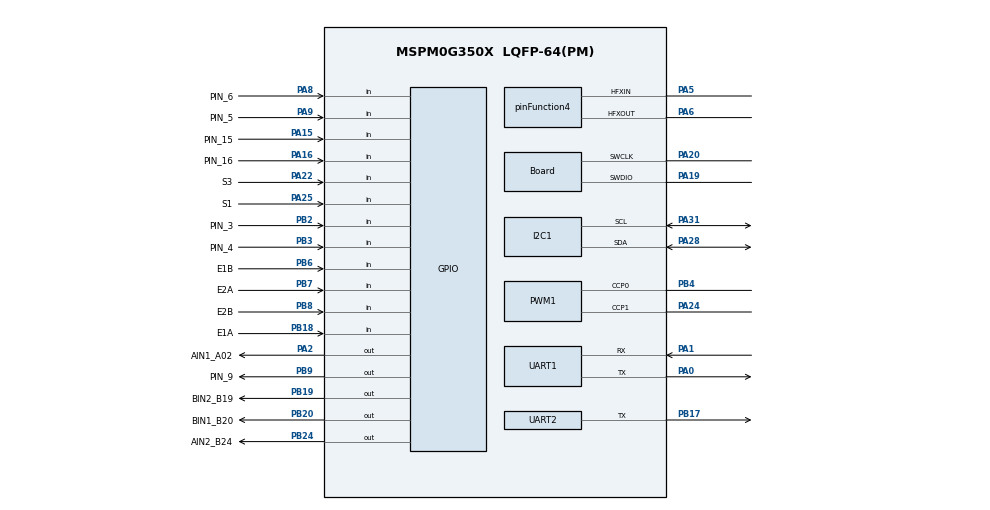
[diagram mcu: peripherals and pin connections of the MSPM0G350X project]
/**
 * @cliArgs --device "MSPM0G350X" --package "LQFP-64(PM)" --part "Default" --product "mspm0_sdk@2.01.00.03"
 * @versions {"tool":"1.20.0+3587"}
 */

/**
 * Import the modules used in this configuration.
 */
const GPIO          = scripting.addModule("/ti/driverlib/GPIO", {}, false);
const GPIO1         = GPIO.addInstance();
const GPIO2         = GPIO.addInstance();
const GPIO3         = GPIO.addInstance();
const GPIO4         = GPIO.addInstance();
const GPIO5         = GPIO.addInstance();
const GPIO6         = GPIO.addInstance();
const GPIO7         = GPIO.addInstance();
const GPIO8         = GPIO.addInstance();
const GPIO9         = GPIO.addInstance();
const GPIO10        = GPIO.addInstance();
const GPIO11        = GPIO.addInstance();
const GPIO12        = GPIO.addInstance();
const GPIO13        = GPIO.addInstance();
const GPIO14        = GPIO.addInstance();
const GPIO15        = GPIO.addInstance();
const GPIO16        = GPIO.addInstance();
const GPIO17        = GPIO.addInstance();
const I2C           = scripting.addModule("/ti/driverlib/I2C", {}, false);
const I2C1          = I2C.addInstance();
const PWM           = scripting.addModule("/ti/driverlib/PWM", {}, false);
const PWM1          = PWM.addInstance();
const PWM2          = PWM.addInstance();
const SYSCTL        = scripting.addModule("/ti/driverlib/SYSCTL");
const SYSTICK       = scripting.addModule("/ti/driverlib/SYSTICK");
const TIMER         = scripting.addModule("/ti/driverlib/TIMER", {}, false);
const TIMER1        = TIMER.addInstance();
const TIMER2        = TIMER.addInstance();
const UART          = scripting.addModule("/ti/driverlib/UART", {}, false);
const UART1         = UART.addInstance();
const UART2         = UART.addInstance();
const UART3         = UART.addInstance();
const UART4         = UART.addInstance();
const ProjectConfig = scripting.addModule("/ti/project_config/ProjectConfig");

/**
 * Write custom configuration values to the imported modules.
 */
const divider9       = system.clockTree["UDIV"];
divider9.divideValue = 2;

const gate7  = system.clockTree["MFCLKGATE"];
gate7.enable = true;

const multiplier2         = system.clockTree["PLL_QDIV"];
multiplier2.multiplyValue = 4;

const mux3       = system.clockTree["EXCLKMUX"];
mux3.inputSelect = "EXCLKMUX_PLLCLK1_OUT";

const mux4       = system.clockTree["EXHFMUX"];
mux4.inputSelect = "EXHFMUX_XTAL";

const mux8       = system.clockTree["HSCLKMUX"];
mux8.inputSelect = "HSCLKMUX_SYSPLL0";

const mux12       = system.clockTree["SYSPLLMUX"];
mux12.inputSelect = "zSYSPLLMUX_HFCLK";

const pinFunction4                        = system.clockTree["HFXT"];
pinFunction4.inputFreq                    = 40;
pinFunction4.enable                       = true;
pinFunction4.HFXTStartup                  = 10;
pinFunction4.peripheral.$assign           = "SYSCTL";
pinFunction4.peripheral.hfxInPin.$assign  = "PA5";
pinFunction4.peripheral.hfxOutPin.$assign = "PA6";

GPIO1.$name                              = "LED1";
GPIO1.port                               = "PORTA";
GPIO1.associatedPins[0].$name            = "PIN_14";
GPIO1.associatedPins[0].assignedPin      = "14";
GPIO1.associatedPins[0].internalResistor = "PULL_UP";

const Board                       = scripting.addModule("/ti/driverlib/Board", {}, false);
Board.peripheral.$assign          = "DEBUGSS";
Board.peripheral.swclkPin.$assign = "PA20";
Board.peripheral.swdioPin.$assign = "PA19";

GPIO2.$name                              = "KEY";
GPIO2.port                               = "PORTA";
GPIO2.associatedPins.create(4);
GPIO2.associatedPins[0].direction        = "INPUT";
GPIO2.associatedPins[0].interruptEn      = true;
GPIO2.associatedPins[0].$name            = "PIN_15";
GPIO2.associatedPins[0].assignedPin      = "15";
GPIO2.associatedPins[0].polarity         = "RISE";
GPIO2.associatedPins[0].internalResistor = "PULL_UP";
GPIO2.associatedPins[0].pin.$assign      = "PA15";
GPIO2.associatedPins[1].$name            = "PIN_16";
GPIO2.associatedPins[1].assignedPin      = "16";
GPIO2.associatedPins[1].direction        = "INPUT";
GPIO2.associatedPins[1].internalResistor = "PULL_UP";
GPIO2.associatedPins[1].pin.$assign      = "PA16";
GPIO2.associatedPins[2].direction        = "INPUT";
GPIO2.associatedPins[2].internalResistor = "PULL_UP";
GPIO2.associatedPins[2].$name            = "PIN_23";
GPIO2.associatedPins[3].assignedPin      = "21";
GPIO2.associatedPins[3].$name            = "PIN_21";
GPIO2.associatedPins[3].direction        = "INPUT";
GPIO2.associatedPins[3].internalResistor = "PULL_UP";

GPIO3.$name                               = "ENCODER";
GPIO3.associatedPins.create(4);
GPIO3.associatedPins[0].$name             = "E1A";
GPIO3.associatedPins[0].direction         = "INPUT";
GPIO3.associatedPins[0].assignedPort      = "PORTB";
GPIO3.associatedPins[0].assignedPin       = "18";
GPIO3.associatedPins[0].interruptEn       = true;
GPIO3.associatedPins[0].interruptPriority = "0";
GPIO3.associatedPins[0].polarity          = "RISE";
GPIO3.associatedPins[0].pin.$assign       = "PB18";
GPIO3.associatedPins[1].$name             = "E1B";
GPIO3.associatedPins[1].direction         = "INPUT";
GPIO3.associatedPins[1].assignedPort      = "PORTB";
GPIO3.associatedPins[1].assignedPin       = "6";
GPIO3.associatedPins[1].interruptEn       = true;
GPIO3.associatedPins[1].interruptPriority = "0";
GPIO3.associatedPins[1].polarity          = "RISE";
GPIO3.associatedPins[1].pin.$assign       = "PB6";
GPIO3.associatedPins[2].$name             = "E2A";
GPIO3.associatedPins[2].direction         = "INPUT";
GPIO3.associatedPins[2].assignedPort      = "PORTB";
GPIO3.associatedPins[2].assignedPin       = "7";
GPIO3.associatedPins[2].interruptEn       = true;
GPIO3.associatedPins[2].interruptPriority = "0";
GPIO3.associatedPins[2].polarity          = "RISE";
GPIO3.associatedPins[2].pin.$assign       = "PB7";
GPIO3.associatedPins[3].$name             = "E2B";
GPIO3.associatedPins[3].direction         = "INPUT";
GPIO3.associatedPins[3].assignedPort      = "PORTB";
GPIO3.associatedPins[3].assignedPin       = "8";
GPIO3.associatedPins[3].interruptEn       = true;
GPIO3.associatedPins[3].interruptPriority = "0";
GPIO3.associatedPins[3].polarity          = "RISE";
GPIO3.associatedPins[3].pin.$assign       = "PB8";

GPIO4.$name                          = "MOTOR";
GPIO4.associatedPins.create(4);
GPIO4.associatedPins[0].$name        = "AIN1_A02";
GPIO4.associatedPins[0].assignedPort = "PORTA";
GPIO4.associatedPins[0].assignedPin  = "2";
GPIO4.associatedPins[0].pin.$assign  = "PA2";
GPIO4.associatedPins[1].$name        = "AIN2_B24";
GPIO4.associatedPins[1].assignedPort = "PORTB";
GPIO4.associatedPins[1].assignedPin  = "24";
GPIO4.associatedPins[1].pin.$assign  = "PB24";
GPIO4.associatedPins[2].$name        = "BIN1_B20";
GPIO4.associatedPins[2].assignedPort = "PORTB";
GPIO4.associatedPins[2].assignedPin  = "20";
GPIO4.associatedPins[2].pin.$assign  = "PB20";
GPIO4.associatedPins[3].$name        = "BIN2_B19";
GPIO4.associatedPins[3].assignedPort = "PORTB";
GPIO4.associatedPins[3].assignedPin  = "19";
GPIO4.associatedPins[3].pin.$assign  = "PB19";

GPIO5.$name                          = "TRACK";
GPIO5.associatedPins.create(3);
GPIO5.associatedPins[0].$name        = "S1";
GPIO5.associatedPins[0].direction    = "INPUT";
GPIO5.associatedPins[0].assignedPort = "PORTA";
GPIO5.associatedPins[0].assignedPin  = "25";
GPIO5.associatedPins[0].pin.$assign  = "PA25";
GPIO5.associatedPins[1].$name        = "S2";
GPIO5.associatedPins[1].direction    = "INPUT";
GPIO5.associatedPins[1].assignedPort = "PORTA";
GPIO5.associatedPins[1].assignedPin  = "12";
GPIO5.associatedPins[2].$name        = "S3";
GPIO5.associatedPins[2].direction    = "INPUT";
GPIO5.associatedPins[2].assignedPort = "PORTA";
GPIO5.associatedPins[2].assignedPin  = "22";
GPIO5.associatedPins[2].pin.$assign  = "PA22";

GPIO6.$name                         = "OLED";
GPIO6.port                          = "PORTB";
GPIO6.associatedPins.create(3);
GPIO6.associatedPins[0].$name       = "RES";
GPIO6.associatedPins[0].assignedPin = "10";
GPIO6.associatedPins[1].$name       = "DC";
GPIO6.associatedPins[1].assignedPin = "1";
GPIO6.associatedPins[2].$name       = "CS";
GPIO6.associatedPins[2].assignedPin = "0";

GPIO7.$name                          = "BEEP";
GPIO7.port                           = "PORTB";
GPIO7.associatedPins[0].$name        = "PIN_12";
GPIO7.associatedPins[0].assignedPin  = "12";
GPIO7.associatedPins[0].initialValue = "SET";

GPIO8.$name                          = "Data";
GPIO8.associatedPins[0].$name        = "PIN_0";
GPIO8.associatedPins[0].direction    = "INPUT";
GPIO8.associatedPins[0].assignedPort = "PORTB";
GPIO8.associatedPins[0].assignedPin  = "15";

GPIO9.$name                              = "CLK";
GPIO9.associatedPins[0].assignedPort     = "PORTA";
GPIO9.associatedPins[0].internalResistor = "PULL_UP";
GPIO9.associatedPins[0].$name            = "CLK_2";

GPIO10.$name                          = "SH";
GPIO10.associatedPins[0].assignedPort = "PORTA";
GPIO10.associatedPins[0].$name        = "SH_2";

GPIO11.$name                         = "GPIO_GRP_0";
GPIO11.associatedPins[0].$name       = "PIN_3";
GPIO11.associatedPins[0].direction   = "INPUT";
GPIO11.associatedPins[0].pin.$assign = "PB2";

GPIO12.$name                         = "GPIO_GRP_1";
GPIO12.associatedPins[0].$name       = "PIN_4";
GPIO12.associatedPins[0].direction   = "INPUT";
GPIO12.associatedPins[0].pin.$assign = "PB3";

GPIO13.$name                         = "GPIO_GRP_2";
GPIO13.associatedPins[0].$name       = "PIN_5";
GPIO13.associatedPins[0].direction   = "INPUT";
GPIO13.associatedPins[0].pin.$assign = "PA9";

GPIO14.$name                         = "GPIO_GRP_3";
GPIO14.associatedPins[0].$name       = "PIN_6";
GPIO14.associatedPins[0].direction   = "INPUT";
GPIO14.associatedPins[0].pin.$assign = "PA8";

GPIO15.$name                         = "LED2";
GPIO15.port                          = "PORTB";
GPIO15.associatedPins[0].$name       = "PIN_9";
GPIO15.associatedPins[0].pin.$assign = "PB9";

GPIO16.$name                   = "GPIO_GRP_4";
GPIO16.port                    = "PORTA";
GPIO16.associatedPins[0].$name = "PIN_13";

GPIO17.$name                   = "GPIO_GRP_8";
GPIO17.associatedPins[0].$name = "PIN_1";

I2C1.basicEnableController             = true;
I2C1.basicClockSourceDivider           = 4;
I2C1.basicControllerBusSpeed           = 500000;
I2C1.$name                             = "I2C_OLED";
I2C1.peripheral.sdaPin.$assign         = "PA28";
I2C1.peripheral.sclPin.$assign         = "PA31";
I2C1.sdaPinConfig.hideOutputInversion  = scripting.forceWrite(false);
I2C1.sdaPinConfig.onlyInternalResistor = scripting.forceWrite(false);
I2C1.sdaPinConfig.passedPeripheralType = scripting.forceWrite("Digital");
I2C1.sdaPinConfig.$name                = "ti_driverlib_gpio_GPIOPinGeneric4";
I2C1.sclPinConfig.hideOutputInversion  = scripting.forceWrite(false);
I2C1.sclPinConfig.onlyInternalResistor = scripting.forceWrite(false);
I2C1.sclPinConfig.passedPeripheralType = scripting.forceWrite("Digital");
I2C1.sclPinConfig.$name                = "ti_driverlib_gpio_GPIOPinGeneric5";

PWM1.$name                              = "PWM_MOTOR";
PWM1.timerCount                         = 10000;
PWM1.timerStartTimer                    = true;
PWM1.peripheral.ccp0Pin.$assign         = "PB4";
PWM1.peripheral.ccp1Pin.$assign         = "PA24";
PWM1.PWM_CHANNEL_0.$name                = "ti_driverlib_pwm_PWMTimerCC0";
PWM1.PWM_CHANNEL_0.invert               = true;
PWM1.PWM_CHANNEL_1.$name                = "ti_driverlib_pwm_PWMTimerCC1";
PWM1.PWM_CHANNEL_1.invert               = true;
PWM1.ccp0PinConfig.$name                = "ti_driverlib_gpio_GPIOPinGeneric2";
PWM1.ccp0PinConfig.direction            = scripting.forceWrite("OUTPUT");
PWM1.ccp0PinConfig.hideOutputInversion  = scripting.forceWrite(false);
PWM1.ccp0PinConfig.onlyInternalResistor = scripting.forceWrite(false);
PWM1.ccp0PinConfig.passedPeripheralType = scripting.forceWrite("Digital");
PWM1.ccp1PinConfig.$name                = "ti_driverlib_gpio_GPIOPinGeneric3";
PWM1.ccp1PinConfig.direction            = scripting.forceWrite("OUTPUT");
PWM1.ccp1PinConfig.hideOutputInversion  = scripting.forceWrite(false);
PWM1.ccp1PinConfig.onlyInternalResistor = scripting.forceWrite(false);
PWM1.ccp1PinConfig.passedPeripheralType = scripting.forceWrite("Digital");

PWM2.$name                              = "PWM_MOTOR_COPY";
PWM2.timerCount                         = 10000;
PWM2.timerStartTimer                    = true;
PWM2.PWM_CHANNEL_0.$name                = "ti_driverlib_pwm_PWMTimerCC0_COPY";
PWM2.PWM_CHANNEL_0.invert               = true;
PWM2.PWM_CHANNEL_1.$name                = "ti_driverlib_pwm_PWMTimerCC1_COPY";
PWM2.PWM_CHANNEL_1.invert               = true;
PWM2.ccp0PinConfig.direction            = scripting.forceWrite("OUTPUT");
PWM2.ccp0PinConfig.hideOutputInversion  = scripting.forceWrite(false);
PWM2.ccp0PinConfig.onlyInternalResistor = scripting.forceWrite(false);
PWM2.ccp0PinConfig.passedPeripheralType = scripting.forceWrite("Digital");
PWM2.ccp0PinConfig.$name                = "ti_driverlib_gpio_GPIOPinGeneric2_COPY";
PWM2.ccp1PinConfig.direction            = scripting.forceWrite("OUTPUT");
PWM2.ccp1PinConfig.hideOutputInversion  = scripting.forceWrite(false);
PWM2.ccp1PinConfig.onlyInternalResistor = scripting.forceWrite(false);
PWM2.ccp1PinConfig.passedPeripheralType = scripting.forceWrite("Digital");
PWM2.ccp1PinConfig.$name                = "ti_driverlib_gpio_GPIOPinGeneric3_COPY";

SYSCTL.forceDefaultClkConfig = true;
SYSCTL.clockTreeEn           = true;
SYSCTL.useHFCLK_Manual       = true;

SYSTICK.periodEnable      = true;
SYSTICK.systickEnable     = true;
SYSTICK.interruptPriority = "0";
SYSTICK.period            = 80;

TIMER1.$name              = "TIMER_0";
TIMER1.timerClkSrc        = "MFCLK";
TIMER1.timerClkPrescale   = 200;
TIMER1.timerStartTimer    = true;
TIMER1.interrupts         = ["ZERO"];
TIMER1.timerMode          = "PERIODIC";
TIMER1.timerPeriod        = "20ms";
TIMER1.interruptPriority  = "0";
TIMER1.peripheral.$assign = "TIMA0";

TIMER2.$name              = "TIMER_1";
TIMER2.timerPeriod        = "5 ms";
TIMER2.timerClkSrc        = "MFCLK";
TIMER2.timerMode          = "PERIODIC";
TIMER2.timerClkPrescale   = 200;
TIMER2.timerStartTimer    = true;
TIMER2.interruptPriority  = "3";
TIMER2.interrupts         = ["ZERO"];
TIMER2.peripheral.$assign = "TIMG6";

UART1.uartClkSrc                       = "MFCLK";
UART1.$name                            = "UART_0_DEBUG";
UART1.interruptPriority                = "3";
UART1.peripheral.$assignAllowConflicts = "UART0";
UART1.peripheral.rxPin.$assign         = "PA1";
UART1.peripheral.txPin.$assign         = "PA0";
UART1.txPinConfig.direction            = scripting.forceWrite("OUTPUT");
UART1.txPinConfig.hideOutputInversion  = scripting.forceWrite(false);
UART1.txPinConfig.onlyInternalResistor = scripting.forceWrite(false);
UART1.txPinConfig.passedPeripheralType = scripting.forceWrite("Digital");
UART1.txPinConfig.$name                = "ti_driverlib_gpio_GPIOPinGeneric0";
UART1.rxPinConfig.hideOutputInversion  = scripting.forceWrite(false);
UART1.rxPinConfig.onlyInternalResistor = scripting.forceWrite(false);
UART1.rxPinConfig.passedPeripheralType = scripting.forceWrite("Digital");
UART1.rxPinConfig.$name                = "ti_driverlib_gpio_GPIOPinGeneric1";

UART2.$name                            = "UART_JY61P";
UART2.uartClkSrc                       = "MFCLK";
UART2.enabledInterrupts                = ["RX"];
UART2.peripheral.$assign               = "UART2";
UART2.peripheral.txPin.$assign         = "PB17";
UART2.txPinConfig.direction            = scripting.forceWrite("OUTPUT");
UART2.txPinConfig.hideOutputInversion  = scripting.forceWrite(false);
UART2.txPinConfig.onlyInternalResistor = scripting.forceWrite(false);
UART2.txPinConfig.passedPeripheralType = scripting.forceWrite("Digital");
UART2.txPinConfig.$name                = "ti_driverlib_gpio_GPIOPinGeneric6";
UART2.rxPinConfig.hideOutputInversion  = scripting.forceWrite(false);
UART2.rxPinConfig.onlyInternalResistor = scripting.forceWrite(false);
UART2.rxPinConfig.passedPeripheralType = scripting.forceWrite("Digital");
UART2.rxPinConfig.$name                = "ti_driverlib_gpio_GPIOPinGeneric7";

UART3.$name                            = "UART_3";
UART3.uartClkSrc                       = "MFCLK";
UART3.txPinConfig.direction            = scripting.forceWrite("OUTPUT");
UART3.txPinConfig.hideOutputInversion  = scripting.forceWrite(false);
UART3.txPinConfig.onlyInternalResistor = scripting.forceWrite(false);
UART3.txPinConfig.passedPeripheralType = scripting.forceWrite("Digital");
UART3.txPinConfig.$name                = "ti_driverlib_gpio_GPIOPinGeneric8";
UART3.rxPinConfig.hideOutputInversion  = scripting.forceWrite(false);
UART3.rxPinConfig.onlyInternalResistor = scripting.forceWrite(false);
UART3.rxPinConfig.passedPeripheralType = scripting.forceWrite("Digital");
UART3.rxPinConfig.$name                = "ti_driverlib_gpio_GPIOPinGeneric9";

UART4.uartClkSrc                       = "MFCLK";
UART4.$name                            = "UART_1";
UART4.txPinConfig.direction            = scripting.forceWrite("OUTPUT");
UART4.txPinConfig.hideOutputInversion  = scripting.forceWrite(false);
UART4.txPinConfig.onlyInternalResistor = scripting.forceWrite(false);
UART4.txPinConfig.passedPeripheralType = scripting.forceWrite("Digital");
UART4.txPinConfig.$name                = "ti_driverlib_gpio_GPIOPinGeneric10";
UART4.rxPinConfig.hideOutputInversion  = scripting.forceWrite(false);
UART4.rxPinConfig.onlyInternalResistor = scripting.forceWrite(false);
UART4.rxPinConfig.passedPeripheralType = scripting.forceWrite("Digital");
UART4.rxPinConfig.$name                = "ti_driverlib_gpio_GPIOPinGeneric11";

ProjectConfig.deviceSpin = "MSPM0G3507";

/**
 * Pinmux solution for unlocked pins/peripherals. This ensures that minor changes to the automatic solver in a future
 * version of the tool will not impact the pinmux you originally saw.  These lines can be completely deleted in order to
 * re-solve from scratch.
 */
GPIO1.associatedPins[0].pin.$suggestSolution  = "PA14";
GPIO2.associatedPins[2].pin.$suggestSolution  = "PA27";
GPIO2.associatedPins[3].pin.$suggestSolution  = "PA21";
GPIO5.associatedPins[1].pin.$suggestSolution  = "PA12";
GPIO6.associatedPins[0].pin.$suggestSolution  = "PB10";
GPIO6.associatedPins[1].pin.$suggestSolution  = "PB1";
GPIO6.associatedPins[2].pin.$suggestSolution  = "PB0";
GPIO7.associatedPins[0].pin.$suggestSolution  = "PB12";
GPIO8.associatedPins[0].pin.$suggestSolution  = "PB15";
GPIO9.associatedPins[0].pin.$suggestSolution  = "PA3";
GPIO10.associatedPins[0].pin.$suggestSolution = "PA30";
GPIO16.associatedPins[0].pin.$suggestSolution = "PA29";
GPIO17.associatedPins[0].pin.$suggestSolution = "PB13";
I2C1.peripheral.$suggestSolution              = "I2C0";
PWM1.peripheral.$suggestSolution              = "TIMA1";
PWM2.peripheral.$suggestSolution              = "TIMG0";
PWM2.peripheral.ccp0Pin.$suggestSolution      = "PA23";
PWM2.peripheral.ccp1Pin.$suggestSolution      = "PB11";
UART2.peripheral.rxPin.$suggestSolution       = "PB16";
UART3.peripheral.$suggestSolution             = "UART3";
UART3.peripheral.rxPin.$suggestSolution       = "PA13";
UART3.peripheral.txPin.$suggestSolution       = "PA26";
UART4.peripheral.$suggestSolution             = "UART1";
UART4.peripheral.rxPin.$suggestSolution       = "PA18";
UART4.peripheral.txPin.$suggestSolution       = "PA17";
